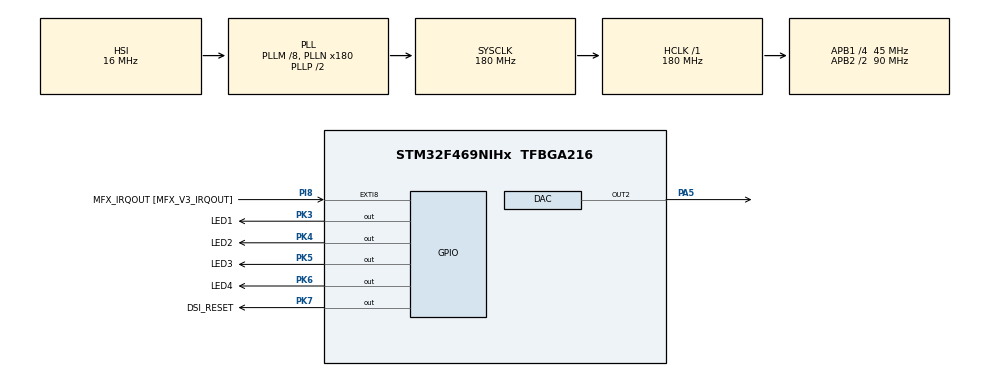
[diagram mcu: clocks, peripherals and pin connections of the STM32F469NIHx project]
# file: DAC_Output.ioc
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DSIHOST_CKN.GPIO_Label=DSI_CK_N
DSIHOST_CKN.Signal=DSIHOST_CKN
DSIHOST_CKP.GPIO_Label=DSI_CK_P
DSIHOST_CKP.Signal=DSIHOST_CKP
DSIHOST_D0N.GPIO_Label=DSI_D0_N
DSIHOST_D0N.Signal=DSIHOST_D0N
DSIHOST_D0P.GPIO_Label=DSI_D0_P
DSIHOST_D0P.Signal=DSIHOST_D0P
DSIHOST_D1N.GPIO_Label=DSI_D1_N
DSIHOST_D1N.Signal=DSIHOST_D1N
DSIHOST_D1P.GPIO_Label=DSI_D1_P
DSIHOST_D1P.Signal=DSIHOST_D1P
Mcu.Family=STM32F4
Mcu.Name=STM32F469NIHx
Mcu.Package=TFBGA216
NVIC.PriorityGroup=NVIC_PRIORITYGROUP_4
PA0/WKUP.GPIO_Label=WAKEUP [B2]
PA0/WKUP.Signal=SYS_WKUP
PA1.GPIO_Label=MII_RX_CLK [DP83848CVV_RX_CLK]
PA1.Signal=ETH_RX_CLK
PA10.GPIO_Label=RS232/IrDA_RX [ST3241EBPR_R3OUT]
PA10.Signal=USART1_RX
PA11.GPIO_Label=USB_FS1_DM
PA11.GPIO_Mode=GPIO_MODE_AF_PP
PA11.GPIO_PuPd=GPIO_NOPULL
PA11.GPIO_Speed=GPIO_SPEED_FREQ_VERY_HIGH
PA11.Signal=USB_OTG_FS_DM
PA12.GPIO_Label=USB_FS1_DP
PA12.GPIO_Mode=GPIO_MODE_AF_PP
PA12.GPIO_PuPd=GPIO_NOPULL
PA12.GPIO_Speed=GPIO_SPEED_FREQ_VERY_HIGH
PA12.Signal=USB_OTG_FS_DP
PA13.GPIO_Label=TMS/SWDIO
PA13.Signal=SYS_JTMS-SWDIO
PA14.GPIO_Label=TCK/SWCLK
PA14.Signal=SYS_JTCK-SWCLK
PA15.GPIO_Label=TDI
PA15.Signal=SYS_JTDI
PA2.GPIO_Label=MII_MDIO [DP83848CVV_MDIO]
PA2.Signal=ETH_MDIO
PA3.GPIO_Label=ULPI_D0 [USB3300-EZK_D0]
PA3.Signal=USB_OTG_HS_ULPI_D0
PA4.GPIO_Label=Potentiometer [RV1]
PA4.Signal=ADCx_IN4
PA5.Signal=COMP_DAC2_group
PA7.GPIO_Label=MII_RX_DV [DP83848CVV_RX_DV]
PA7.Signal=ETH_RX_DV
PA8.GPIO_Label=LCD_BL_CTRL
PA8.Signal=S_TIM1_CH1
PA9.GPIO_Label=RS232/IrDA_TX [ST3241EBPR_T2IN]
PA9.Signal=USART1_TX
PB0.GPIO_Label=ULPI_D1 [USB3300-EZK_D1]
PB0.Signal=USB_OTG_HS_ULPI_D1
PB1.GPIO_Label=ULPI_D2 [USB3300-EZK_D2]
PB1.Signal=USB_OTG_HS_ULPI_D2
PB10.GPIO_Label=ULPI_D3 [USB3300-EZK_D3]
PB10.Signal=USB_OTG_HS_ULPI_D3
PB11.GPIO_Label=ULPI_D4 [USB3300-EZK_D4]
PB11.Signal=USB_OTG_HS_ULPI_D4
PB12.GPIO_Label=ULPI_D5 [USB3300-EZK_D5]
PB12.Signal=USB_OTG_HS_ULPI_D5
PB13.GPIO_Label=ULPI_D6 [USB3300-EZK_D6]
PB13.Signal=USB_OTG_HS_ULPI_D6
PB14.GPIO_Label=USB_FS2_DM
PB14.Signal=USB_OTG_HS_DM
PB15.GPIO_Label=USB_FS2_DP
PB15.Signal=USB_OTG_HS_DP
PB3.GPIO_Label=TDO-SWO
PB3.Signal=SYS_JTDO-SWO
PB4.GPIO_Label=TRST
PB4.Signal=SYS_JTRST
PB5.GPIO_Label=ULPI_D7 [USB3300-EZK_D7]
PB5.GPIO_Mode=GPIO_MODE_AF_PP
PB5.GPIO_PuPd=GPIO_NOPULL
PB5.GPIO_Speed=GPIO_SPEED_FREQ_VERY_HIGH
PB5.Signal=USB_OTG_HS_ULPI_D7
PB6.GPIO_Label=QSPI_BK1_NCS [MT25QL512ABA8ESF-0SIT_CS\#]
PB6.GPIO_Mode=GPIO_MODE_AF_PP
PB6.GPIO_PuPd=GPIO_NOPULL
PB6.GPIO_Speed=GPIO_SPEED_FREQ_VERY_HIGH
PB6.Signal=QUADSPI_BK1_NCS
PB7.GPIO_Label=PAR_VSYNC
PB7.GPIO_Mode=GPIO_MODE_AF_PP
PB7.GPIO_PuPd=GPIO_NOPULL
PB7.GPIO_Speed=GPIO_SPEED_FREQ_LOW
PB7.Signal=DCMI_VSYNC
PB8.GPIO_Label=I2C1_SCL [WM8994ECS/R_SLCK]
PB8.GPIO_Mode=GPIO_MODE_AF_OD
PB8.GPIO_PuPdOD=GPIO_PULLUP
PB8.GPIO_Speed=GPIO_SPEED_FREQ_VERY_HIGH
PB8.Signal=I2C1_SCL
PB9.GPIO_Label=I2C1_SDA [WM8994ECS/R_SDA]
PB9.GPIO_Mode=GPIO_MODE_AF_OD
PB9.GPIO_PuPdOD=GPIO_PULLUP
PB9.GPIO_Speed=GPIO_SPEED_FREQ_VERY_HIGH
PB9.Signal=I2C1_SDA
PC0.GPIO_Label=ULPI_STP [USB3300-EZK_STP]
PC0.Signal=USB_OTG_HS_ULPI_STP
PC1.GPIO_Label=MII_MDC [DP83848CVV_MDC]
PC1.Signal=ETH_MDC
PC10.GPIO_Label=uSD_D2
PC10.GPIO_Mode=GPIO_MODE_AF_PP
PC10.GPIO_PuPd=GPIO_NOPULL
PC10.GPIO_Speed_High_Default=GPIO_SPEED_FREQ_VERY_HIGH
PC10.Signal=SDIO_D2
PC11.GPIO_Label=uSD_D3
PC11.GPIO_Mode=GPIO_MODE_AF_PP
PC11.GPIO_PuPd=GPIO_NOPULL
PC11.GPIO_Speed_High_Default=GPIO_SPEED_FREQ_VERY_HIGH
PC11.Signal=SDIO_D3
PC12.GPIO_Label=uSD_CLK
PC12.GPIO_Mode=GPIO_MODE_AF_PP
PC12.GPIO_PuPd=GPIO_NOPULL
PC12.GPIO_Speed_High_Default=GPIO_SPEED_FREQ_VERY_HIGH
PC12.Signal=SDIO_CK
PC13.GPIO_Label=TAMPER_KEY [B3]
PC13.Signal=RTC_AF1
PC14/OSC32_IN.Signal=RCC_OSC32_IN
PC15/OSC32_OUT.Signal=RCC_OSC32_OUT
PC2.GPIO_Label=MII_TXD2 [DP83848CVV_TXD_2]
PC2.Signal=ETH_TXD2
PC3.GPIO_Label=MII_TX_CLK [DP83848CVV_TX_CLK]
PC3.Signal=ETH_TX_CLK
PC4.GPIO_Label=MII_RXD0 [DP83848CVV_RXD_0]
PC4.Signal=ETH_RXD0
PC5.GPIO_Label=MII_RXD1 [DP83848CVV_RXD_1]
PC5.Signal=ETH_RXD1
PC6.GPIO_Label=I2S3_CK
PC6.Signal=S_TIM8_CH1
PC7.GPIO_Label=MIK_CK
PC7.Signal=S_TIM8_CH2
PC8.GPIO_Label=uSD_D0
PC8.Signal=SDIO_D0
PC9.GPIO_Label=uSD_D1
PC9.Signal=SDIO_D1
PD0.GPIO_Label=D2
PD0.GPIO_Mode=GPIO_MODE_AF_PP
PD0.GPIO_PuPd=GPIO_NOPULL
PD0.GPIO_Speed_High_Default=GPIO_SPEED_FREQ_VERY_HIGH
PD0.Signal=FMC_D2_DA2
PD1.GPIO_Label=D3
PD1.GPIO_Mode=GPIO_MODE_AF_PP
PD1.GPIO_PuPd=GPIO_NOPULL
PD1.GPIO_Speed_High_Default=GPIO_SPEED_FREQ_VERY_HIGH
PD1.Signal=FMC_D3_DA3
PD10.GPIO_Label=D15
PD10.Signal=FMC_D15_DA15
PD11.GPIO_Label=A16
PD11.Signal=FMC_A16_CLE
PD12.GPIO_Label=A17
PD12.Signal=FMC_A17_ALE
PD13.GPIO_Label=A18
PD13.Signal=FMC_A18
PD14.GPIO_Label=D0
PD14.Signal=FMC_D0_DA0
PD15.GPIO_Label=D1
PD15.Signal=FMC_D1_DA1
PD2.GPIO_Label=uSD_CMD
PD2.Signal=SDIO_CMD
PD4.GPIO_Label=FMC_NOE [CY7C1071DV33-12BAXI_OE]
PD4.Signal=FMC_NOE
PD5.GPIO_Label=FMC_NOE [CY7C1071DV33-12BAXI_OE]
PD5.GPIO_Mode=GPIO_MODE_AF_PP
PD5.GPIO_PuPd=GPIO_NOPULL
PD5.GPIO_Speed_High_Default=GPIO_SPEED_FREQ_VERY_HIGH
PD5.Signal=FMC_NWE
PD6.GPIO_Label=FMC_NWAIT [S29GL128S90FHI02_RB]
PD6.GPIO_Mode=GPIO_MODE_AF_PP
PD6.GPIO_PuPd=GPIO_NOPULL
PD6.GPIO_Speed_High_Default=GPIO_SPEED_FREQ_VERY_HIGH
PD6.Signal=FMC_NWAIT
PD7.GPIO_Label=FMC_NE1 [S29GL128S90FHI02_E]
PD7.GPIO_Mode=GPIO_MODE_AF_PP
PD7.GPIO_PuPd=GPIO_NOPULL
PD7.GPIO_Speed_High_Default=GPIO_SPEED_FREQ_VERY_HIGH
PD7.Signal=FMC_NE1
PD8.GPIO_Label=D13
PD8.Signal=FMC_D13_DA13
PD9.GPIO_Label=D14
PD9.Signal=FMC_D14_DA14
PE0.GPIO_Label=FMC_NBL0_CY7C1071DV33]
PE0.GPIO_Mode=GPIO_MODE_AF_PP
PE0.GPIO_PuPd=GPIO_NOPULL
PE0.GPIO_Speed_High_Default=GPIO_SPEED_FREQ_VERY_HIGH
PE0.Signal=FMC_NBL0
PE1.GPIO_Label=FMC_NBL1 [CY7C1071DV33_BHE]
PE1.GPIO_Mode=GPIO_MODE_AF_PP
PE1.GPIO_PuPd=GPIO_NOPULL
PE1.GPIO_Speed_High_Default=GPIO_SPEED_FREQ_VERY_HIGH
PE1.Signal=FMC_NBL1
PE10.GPIO_Label=D7
PE10.Signal=FMC_D7_DA7
PE11.GPIO_Label=D8
PE11.Signal=FMC_D8_DA8
PE12.GPIO_Label=D9
PE12.Signal=FMC_D9_DA9
PE13.GPIO_Label=D10
PE13.Signal=FMC_D10_DA10
PE14.GPIO_Label=D11
PE14.Signal=FMC_D11_DA11
PE15.GPIO_Label=D12
PE15.Signal=FMC_D12_DA12
PE2.GPIO_Label=MII_TXD3
PE2.GPIO_Mode=GPIO_MODE_AF_PP
PE2.GPIO_PuPd=GPIO_NOPULL
PE2.GPIO_Speed=GPIO_SPEED_FREQ_VERY_HIGH
PE2.Signal=ETH_TXD3
PE3.GPIO_Label=A19
PE3.GPIO_Mode=GPIO_MODE_AF_PP
PE3.GPIO_PuPd=GPIO_NOPULL
PE3.GPIO_Speed_High_Default=GPIO_SPEED_FREQ_VERY_HIGH
PE3.Signal=FMC_A19
PE4.GPIO_Label=A20
PE4.GPIO_Mode=GPIO_MODE_AF_PP
PE4.GPIO_PuPd=GPIO_NOPULL
PE4.GPIO_Speed_High_Default=GPIO_SPEED_FREQ_VERY_HIGH
PE4.Signal=FMC_A20
PE5.GPIO_Label=A21 [S29GL128S90FHI02_A21]
PE5.GPIO_Mode=GPIO_MODE_AF_PP
PE5.GPIO_PuPd=GPIO_NOPULL
PE5.GPIO_Speed_High_Default=GPIO_SPEED_FREQ_VERY_HIGH
PE5.Signal=FMC_A21
PE6.GPIO_Label=A22 [S29GL128S90FHI02_A22]
PE6.GPIO_Mode=GPIO_MODE_AF_PP
PE6.GPIO_PuPd=GPIO_NOPULL
PE6.GPIO_Speed_High_Default=GPIO_SPEED_FREQ_VERY_HIGH
PE6.Signal=FMC_A22
PE7.GPIO_Label=D4
PE7.Signal=FMC_D4_DA4
PE8.GPIO_Label=D5
PE8.Signal=FMC_D5_DA5
PE9.GPIO_Label=D6
PE9.Signal=FMC_D6_DA6
PF0.GPIO_Label=A0
PF0.GPIO_Mode=GPIO_MODE_AF_PP
PF0.GPIO_PuPd=GPIO_NOPULL
PF0.GPIO_Speed_High_Default=GPIO_SPEED_FREQ_VERY_HIGH
PF0.Signal=FMC_A0
PF1.GPIO_Label=A1
PF1.Signal=FMC_A1
PF10.GPIO_Label=QSPI_CLK [MT25QL512ABA8ESF-0SIT_CLK]
PF10.Signal=QUADSPI_CLK
PF11.GPIO_Label=SDNRAS [MT48LC4M32B2B5-7_RAS]
PF11.Signal=FMC_SDNRAS
PF12.GPIO_Label=A6
PF12.Signal=FMC_A6
PF13.GPIO_Label=A7
PF13.Signal=FMC_A7
PF14.GPIO_Label=A8
PF14.Signal=FMC_A8
PF15.GPIO_Label=A9
PF15.Signal=FMC_A9
PF2.GPIO_Label=A2
PF2.Signal=FMC_A2
PF3.GPIO_Label=A3
PF3.Signal=FMC_A3
PF4.GPIO_Label=A4
PF4.Signal=FMC_A4
PF5.GPIO_Label=A5
PF5.Signal=FMC_A5
PF6.GPIO_Label=QSPI_BK1_IO3 [MT25QL512ABA8ESF-0SIT_DQ3]
PF6.Signal=QUADSPI_BK1_IO3
PF7.GPIO_Label=QSPI_BK1_IO2 [MT25QL512ABA8ESF-0SIT_DQ2]
PF7.Signal=QUADSPI_BK1_IO2
PF8.GPIO_Label=QSPI_BK1_IO0 [MT25QL512ABA8ESF-0SIT_DQ0]
PF8.Signal=QUADSPI_BK1_IO0
PF9.GPIO_Label=QSPI_BK1_IO1 [MT25QL512ABA8ESF-0SIT_DQ1]
PF9.Signal=QUADSPI_BK1_IO1
PG0.GPIO_Label=A10
PG0.Signal=FMC_A10
PG1.GPIO_Label=A11
PG1.Signal=FMC_A11
PG11.GPIO_Label=MII_TX_EN [DP83848CVV_TXEN]
PG11.GPIO_Mode=GPIO_MODE_AF_PP
PG11.GPIO_PuPd=GPIO_NOPULL
PG11.GPIO_Speed=GPIO_SPEED_FREQ_VERY_HIGH
PG11.Signal=ETH_TX_EN
PG13.GPIO_Label=MII_TXD0
PG13.Signal=ETH_TXD0
PG14.GPIO_Label=MII_TXD1
PG14.GPIO_Mode=GPIO_MODE_AF_PP
PG14.GPIO_PuPd=GPIO_NOPULL
PG14.GPIO_Speed=GPIO_SPEED_FREQ_VERY_HIGH
PG14.Signal=ETH_TXD1
PG15.GPIO_Label=SDNCAS [MT48LC4M32B2B5-7_CAS\#]
PG15.GPIO_Mode=GPIO_MODE_AF_PP
PG15.GPIO_PuPd=GPIO_NOPULL
PG15.GPIO_Speed_High_Default=GPIO_SPEED_FREQ_VERY_HIGH
PG15.Signal=FMC_SDNCAS
PG2.GPIO_Label=A12
PG2.Signal=FMC_A12
PG3.GPIO_Label=A13
PG3.Signal=FMC_A13
PG4.GPIO_Label=A14
PG4.Signal=FMC_A14_BA0
PG5.GPIO_Label=A15
PG5.Signal=FMC_A15_BA1
PG7.GPIO_Label=SAI1_MCLKA [WM8994ECS/R_MCLK1]
PG7.Signal=SAI1_MCLK_A
PG8.GPIO_Label=SDCLK [MT48LC4M32B2B5-7_CLK]
PG8.Signal=FMC_SDCLK
PG9.GPIO_Label=FMC_NE2 [CY7C1071DV33-12BAXI_CE]
PG9.Signal=FMC_NE2
PH0/OSC_IN.GPIO_Label=OSC_IN
PH0/OSC_IN.Signal=RCC_OSC_IN
PH1/OSC_OUT.GPIO_Label=OSC_OUT
PH1/OSC_OUT.Signal=RCC_OSC_OUT
PH10.GPIO_Label=D18
PH10.Signal=FMC_D18
PH11.GPIO_Label=D19
PH11.Signal=FMC_D19
PH12.GPIO_Label=D20
PH12.Signal=FMC_D20
PH13.GPIO_Label=D21
PH13.Signal=FMC_D21
PH14.GPIO_Label=D22
PH14.Signal=FMC_D22
PH15.GPIO_Label=D23
PH15.Signal=FMC_D23
PH2.GPIO_Label=SDCKE0 [MT48LC4M32B2B5-7_CKE]
PH2.Signal=FMC_SDCKE0
PH3.GPIO_Label=SDNE0 [MT48LC4M32B2B5-7_CS]
PH3.Signal=FMC_SDNE0
PH4.GPIO_Label=ULPI_NXT [USB3300-EZK_NXT]
PH4.Signal=USB_OTG_HS_ULPI_NXT
PH5.GPIO_Label=SDNWE [MT48LC4M32B2B5-7_WE]
PH5.Signal=FMC_SDNWE
PH6.GPIO_Label=MII_RXD2 [DP83848CVV_RXD_2]
PH6.Signal=ETH_RXD2
PH7.GPIO_Label=MII_RXD3 [DP83848CVV_RXD_3]
PH7.Signal=ETH_RXD3
PH8.GPIO_Label=D16
PH8.Signal=FMC_D16
PH9.GPIO_Label=D17
PH9.Signal=FMC_D17
PI0.GPIO_Label=D24
PI0.Signal=FMC_D24
PI1.GPIO_Label=D25
PI1.Signal=FMC_D25
PI10.GPIO_Label=D31
PI10.GPIO_Mode=GPIO_MODE_AF_PP
PI10.GPIO_PuPd=GPIO_NOPULL
PI10.GPIO_Speed_High_Default=GPIO_SPEED_FREQ_VERY_HIGH
PI10.Signal=FMC_D31
PI11.GPIO_Label=ULPI_DIR [USB3300-EZK_DIR]
PI11.Signal=USB_OTG_HS_ULPI_DIR
PI2.GPIO_Label=D26
PI2.GPIO_Mode=GPIO_MODE_AF_PP
PI2.GPIO_PuPd=GPIO_NOPULL
PI2.GPIO_Speed_High_Default=GPIO_SPEED_FREQ_VERY_HIGH
PI2.Signal=FMC_D26
PI3.GPIO_Label=D27
PI3.GPIO_Mode=GPIO_MODE_AF_PP
PI3.GPIO_PuPd=GPIO_NOPULL
PI3.GPIO_Speed_High_Default=GPIO_SPEED_FREQ_VERY_HIGH
PI3.Signal=FMC_D27
PI4.GPIO_Label=FMC_NBL2 [MT48LC4M32B2B5-7_DQM2]
PI4.GPIO_Mode=GPIO_MODE_AF_PP
PI4.GPIO_PuPd=GPIO_NOPULL
PI4.GPIO_Speed_High_Default=GPIO_SPEED_FREQ_VERY_HIGH
PI4.Signal=FMC_NBL2
PI5.GPIO_Label=FMC_NBL3 [MT48LC4M32B2B5-7_DGQM3]
PI5.GPIO_Mode=GPIO_MODE_AF_PP
PI5.GPIO_PuPd=GPIO_NOPULL
PI5.GPIO_Speed_High_Default=GPIO_SPEED_FREQ_VERY_HIGH
PI5.Signal=FMC_NBL3
PI6.GPIO_Label=D28
PI6.GPIO_Mode=GPIO_MODE_AF_PP
PI6.GPIO_PuPd=GPIO_NOPULL
PI6.GPIO_Speed_High_Default=GPIO_SPEED_FREQ_VERY_HIGH
PI6.Signal=FMC_D28
PI7.GPIO_Label=D29
PI7.GPIO_Mode=GPIO_MODE_AF_PP
PI7.GPIO_PuPd=GPIO_NOPULL
PI7.GPIO_Speed_High_Default=GPIO_SPEED_FREQ_VERY_HIGH
PI7.Signal=FMC_D29
PI8.GPIO_Label=MFX_IRQOUT [MFX_V3_IRQOUT]
PI8.GPIO_ModeDefaultEXTI=GPIO_MODE_IT_RISING
PI8.GPIO_PuPd=GPIO_NOPULL
PI8.Signal=GPXTI8
PI9.GPIO_Label=D30
PI9.Signal=FMC_D30
PJ2.GPIO_Label=DSI_TE
PJ2.Signal=DSIHOST_TE
PK3.GPIO_Label=LED1
PK3.GPIO_ModeDefaultOutputPP=GPIO_MODE_OUTPUT_OD
PK3.GPIO_PuPd=GPIO_NOPULL
PK3.GPIO_Speed=GPIO_SPEED_FREQ_LOW
PK3.Signal=GPIO_Output
PK4.GPIO_Label=LED2
PK4.GPIO_ModeDefaultOutputPP=GPIO_MODE_OUTPUT_OD
PK4.GPIO_PuPd=GPIO_NOPULL
PK4.GPIO_Speed=GPIO_SPEED_FREQ_LOW
PK4.Signal=GPIO_Output
PK5.GPIO_Label=LED3
PK5.GPIO_ModeDefaultOutputPP=GPIO_MODE_OUTPUT_OD
PK5.GPIO_PuPd=GPIO_NOPULL
PK5.GPIO_Speed=GPIO_SPEED_FREQ_LOW
PK5.Signal=GPIO_Output
PK6.GPIO_Label=LED4
PK6.GPIO_ModeDefaultOutputPP=GPIO_MODE_OUTPUT_OD
PK6.GPIO_PuPd=GPIO_NOPULL
PK6.GPIO_Speed=GPIO_SPEED_FREQ_LOW
PK6.Signal=GPIO_Output
PK7.GPIO_Label=DSI_RESET
PK7.GPIO_ModeDefaultOutputPP=GPIO_MODE_OUTPUT_PP
PK7.GPIO_PuPd=GPIO_NOPULL
PK7.GPIO_Speed=GPIO_SPEED_FREQ_LOW
PK7.Signal=GPIO_Output
ProjectManager.HeapSize=0x200
ProjectManager.StackSize=0x400
ProjectManager.TargetToolchain=MDK-ARM V5.32
RCC.AHBFreq_Value=180000000
RCC.APB1CLKDivider=RCC_HCLK_DIV4
RCC.APB1Freq_Value=45000000
RCC.APB1TimFreq_Value=90000000
RCC.APB2CLKDivider=RCC_HCLK_DIV2
RCC.APB2Freq_Value=90000000
RCC.APB2TimFreq_Value=180000000
RCC.CortexFreq_Value=180000000
RCC.HCLKFreq_Value=180000000
RCC.PLLM=8
RCC.PLLN=180
RCC.SYSCLKFreq_VALUE=180000000
RCC.SYSCLKSource=RCC_SYSCLKSOURCE_PLLCLK
RCC.USBFreq_Value=90000000
RCC.VCOOutputFreq_Value=360000000
SH.ADCx_IN4.0=ADC1_IN4
SH.COMP_DAC2_group.0=DAC_OUT2,DAC_OUT2
SH.FMC_A0.0=FMC_A0
SH.FMC_A1.0=FMC_A1
SH.FMC_A10.0=FMC_A10
SH.FMC_A11.0=FMC_A11
SH.FMC_A12.0=FMC_A12
SH.FMC_A13.0=FMC_A13
SH.FMC_A14_BA0.0=FMC_A14
SH.FMC_A15_BA1.0=FMC_A15
SH.FMC_A16_CLE.0=FMC_A16
SH.FMC_A17_ALE.0=FMC_A17
SH.FMC_A18.0=FMC_A18
SH.FMC_A19.0=FMC_A19
SH.FMC_A2.0=FMC_A2
SH.FMC_A20.0=FMC_A20
SH.FMC_A21.0=FMC_A21
SH.FMC_A22.0=FMC_A22
SH.FMC_A3.0=FMC_A3
SH.FMC_A4.0=FMC_A4
SH.FMC_A5.0=FMC_A5
SH.FMC_A6.0=FMC_A6
SH.FMC_A7.0=FMC_A7
SH.FMC_A8.0=FMC_A8
SH.FMC_A9.0=FMC_A9
SH.FMC_D0_DA0.0=FMC_D0
SH.FMC_D10_DA10.0=FMC_D10
SH.FMC_D11_DA11.0=FMC_D11
SH.FMC_D12_DA12.0=FMC_D12
SH.FMC_D13_DA13.0=FMC_D13
SH.FMC_D14_DA14.0=FMC_D14
SH.FMC_D15_DA15.0=FMC_D15
SH.FMC_D16.0=FMC_D16
SH.FMC_D17.0=FMC_D17
SH.FMC_D18.0=FMC_D18
SH.FMC_D19.0=FMC_D19
SH.FMC_D1_DA1.0=FMC_D1
SH.FMC_D20.0=FMC_D20
SH.FMC_D21.0=FMC_D21
SH.FMC_D22.0=FMC_D22
SH.FMC_D23.0=FMC_D23
SH.FMC_D24.0=FMC_D24
SH.FMC_D25.0=FMC_D25
SH.FMC_D26.0=FMC_D26
SH.FMC_D27.0=FMC_D27
SH.FMC_D28.0=FMC_D28
SH.FMC_D29.0=FMC_D29
SH.FMC_D2_DA2.0=FMC_D2
SH.FMC_D30.0=FMC_D30
SH.FMC_D31.0=FMC_D31
SH.FMC_D3_DA3.0=FMC_D3
SH.FMC_D4_DA4.0=FMC_D4
SH.FMC_D5_DA5.0=FMC_D5
SH.FMC_D6_DA6.0=FMC_D6
SH.FMC_D7_DA7.0=FMC_D7
SH.FMC_D8_DA8.0=FMC_D8
SH.FMC_D9_DA9.0=FMC_D9
SH.FMC_NBL0.0=FMC_NBL0
SH.FMC_NBL1.0=FMC_NBL1
SH.FMC_NBL2.0=FMC_NBL2
SH.FMC_NBL3.0=FMC_NBL3
SH.FMC_NOE.0=FMC_NOE
SH.FMC_NWAIT.0=FMC_NWAIT
SH.FMC_NWE.0=FMC_NWE
SH.FMC_SDCLK.0=FMC_SDCLK
SH.FMC_SDNCAS.0=FMC_SDNCAS
SH.FMC_SDNRAS.0=FMC_SDNRAS
SH.FMC_SDNWE.0=FMC_SDNWE
SH.S_TIM1_CH1.0=TIM1_CH1
SH.S_TIM8_CH1.0=TIM8_CH1
SH.S_TIM8_CH2.0=TIM8_CH2
board=STM32469I-EVAL

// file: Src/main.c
/* USER CODE BEGIN Header */
/**
  ******************************************************************************
  * @file           : main.c
  * @brief          : Main program body
  ******************************************************************************
  * @attention
  *
  * Copyright (c) 2022 STMicroelectronics.
  * All rights reserved.
  *
  * This software is licensed under terms that can be found in the LICENSE file
  * in the root directory of this software component.
  * If no LICENSE file comes with this software, it is provided AS-IS.
  *
  ******************************************************************************
  */
/* USER CODE END Header */
#include "main.h"
#include "dac.h"
#include "gpio.h"

/* USER CODE BEGIN Includes */
#include "math.h"
/* USER CODE END Includes */

/* USER CODE BEGIN PD */
#define MAX_VOLTAGE				3.0
/* USER CODE END PD */

/* USER CODE BEGIN PV */
float VoltageValue = 0.2;
uint8_t ByteValue;
/* USER CODE END PV */

void SystemClock_Config(void);

int main(void)
{
  /* USER CODE BEGIN 1 */
	int counter = 0;
  /* USER CODE END 1 */

  /* MCU Configuration--------------------------------------------------------*/

  /* Reset of all peripherals, Initializes the Flash interface and the Systick. */
  HAL_Init();

  /* Configure the system clock */
  SystemClock_Config();

  /* Initialize all configured peripherals */
  MX_GPIO_Init();
  MX_DAC_Init();
  /* USER CODE BEGIN 2 */

	 ByteValue = (uint8_t)(VoltageValue/3.3) * 255;
	 HAL_DAC_SetValue(&hdac, DAC_CHANNEL_1, DAC_ALIGN_8B_R, ByteValue);
	 VoltageValue += 0.5;

	/* USER CODE END 2 */

  /* Infinite loop */
  while (1)
  {

  }
}

void SystemClock_Config(void)
{
  RCC_OscInitTypeDef RCC_OscInitStruct = {0};
  RCC_ClkInitTypeDef RCC_ClkInitStruct = {0};

  /** Configure the main internal regulator output voltage
  */
  __HAL_RCC_PWR_CLK_ENABLE();
  __HAL_PWR_VOLTAGESCALING_CONFIG(PWR_REGULATOR_VOLTAGE_SCALE1);

  /** Initializes the RCC Oscillators according to the specified parameters
  * in the RCC_OscInitTypeDef structure.
  */
  RCC_OscInitStruct.OscillatorType = RCC_OSCILLATORTYPE_HSI;
  RCC_OscInitStruct.HSIState = RCC_HSI_ON;
  RCC_OscInitStruct.HSICalibrationValue = RCC_HSICALIBRATION_DEFAULT;
  RCC_OscInitStruct.PLL.PLLState = RCC_PLL_ON;
  RCC_OscInitStruct.PLL.PLLSource = RCC_PLLSOURCE_HSI;
  RCC_OscInitStruct.PLL.PLLM = 8;
  RCC_OscInitStruct.PLL.PLLN = 180;
  RCC_OscInitStruct.PLL.PLLP = RCC_PLLP_DIV2;
  RCC_OscInitStruct.PLL.PLLQ = 4;
  RCC_OscInitStruct.PLL.PLLR = 2;
  if (HAL_RCC_OscConfig(&RCC_OscInitStruct) != HAL_OK)
  {
    Error_Handler();
  }

  /** Activate the Over-Drive mode
  */
  if (HAL_PWREx_EnableOverDrive() != HAL_OK)
  {
    Error_Handler();
  }

  /** Initializes the CPU, AHB and APB buses clocks
  */
  RCC_ClkInitStruct.ClockType = RCC_CLOCKTYPE_HCLK|RCC_CLOCKTYPE_SYSCLK
                              |RCC_CLOCKTYPE_PCLK1|RCC_CLOCKTYPE_PCLK2;
  RCC_ClkInitStruct.SYSCLKSource = RCC_SYSCLKSOURCE_PLLCLK;
  RCC_ClkInitStruct.AHBCLKDivider = RCC_SYSCLK_DIV1;
  RCC_ClkInitStruct.APB1CLKDivider = RCC_HCLK_DIV4;
  RCC_ClkInitStruct.APB2CLKDivider = RCC_HCLK_DIV2;

  if (HAL_RCC_ClockConfig(&RCC_ClkInitStruct, FLASH_LATENCY_5) != HAL_OK)
  {
    Error_Handler();
  }
}

void Error_Handler(void)
{
  __disable_irq();
  while (1)
  {
  }
}
